CM_ "IMPORT _community.dbc";
CM_ "IMPORT _toyota_2017.dbc";
CM_ "IMPORT _toyota_adas_standard.dbc";

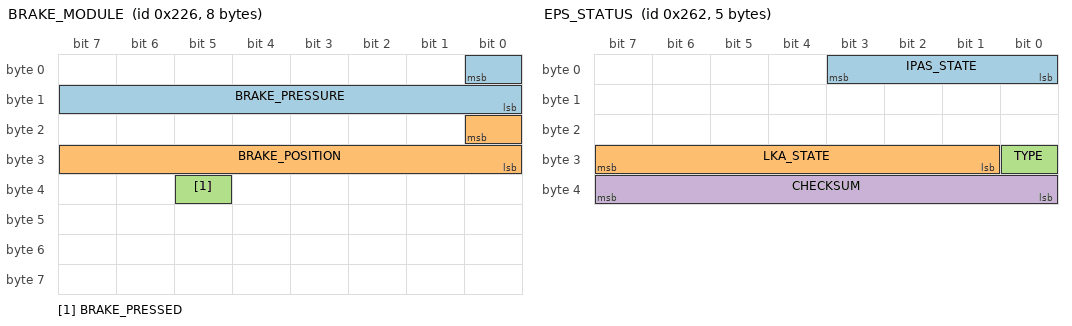
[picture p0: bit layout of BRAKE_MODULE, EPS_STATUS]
BO_ 550 BRAKE_MODULE: 8 XXX
 SG_ BRAKE_PRESSURE : 0|9@0+ (1,0) [0|511] "" XXX
 SG_ BRAKE_POSITION : 16|9@0+ (1,0) [0|511] "" XXX
 SG_ BRAKE_PRESSED : 37|1@0+ (1,0) [0|1] "" XXX

BO_ 610 EPS_STATUS: 5 EPS
 SG_ IPAS_STATE : 3|4@0+ (1,0) [0|15] "" XXX
 SG_ LKA_STATE : 31|7@0+ (1,0) [0|127] "" XXX
 SG_ TYPE : 24|1@0+ (1,0) [0|1] "" XXX
 SG_ CHECKSUM : 39|8@0+ (1,0) [0|255] "" XXX

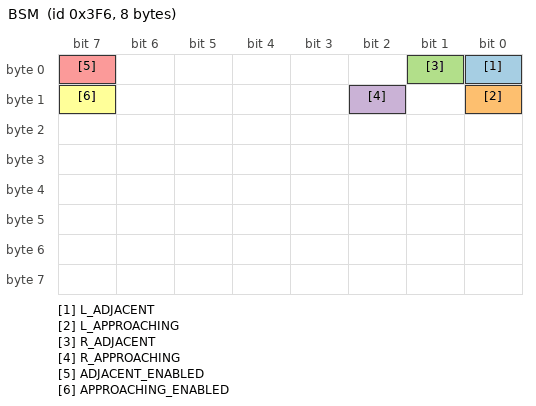
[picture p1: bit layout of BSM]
BO_ 1014 BSM: 8 XXX
 SG_ L_ADJACENT : 0|1@0+ (1,0) [0|1] "" XXX
 SG_ L_APPROACHING : 8|1@0+ (1,0) [0|1] "" XXX
 SG_ R_ADJACENT : 1|1@0+ (1,0) [0|1] "" XXX
 SG_ R_APPROACHING : 10|1@0+ (1,0) [0|1] "" XXX
 SG_ ADJACENT_ENABLED : 7|1@0+ (1,0) [0|1] "" XXX
 SG_ APPROACHING_ENABLED : 15|1@0+ (1,0) [0|1] "" XXX

CM_ SG_ 550 BRAKE_PRESSURE "seems prop to pedal force";
CM_ SG_ 550 BRAKE_POSITION "seems proportional to pedal displacement, unclear the max value of 0x1c8";
CM_ SG_ 610 TYPE "seems 1 on Corolla, 0 on all others";
CM_ SG_ 1014 L_ADJACENT "vehicle adjacent left side of car. enabled above 10mph, regardless of ADJACENT_ENABLED or APPROACHING_ENABLED";
CM_ SG_ 1014 L_APPROACHING "vehicle approaching from left side of car. enabled above 10mph, regardless of ADJACENT_ENABLED or APPROACHING_ENABLED";
CM_ SG_ 1014 R_ADJACENT "vehicle adjacent right side of car. enabled above 10mph, regardless of ADJACENT_ENABLED or APPROACHING_ENABLED";
CM_ SG_ 1014 R_APPROACHING "vehicle approaching from right side of car. enabled above 10mph, regardless of ADJACENT_ENABLED or APPROACHING_ENABLED";
CM_ SG_ 1014 ADJACENT_ENABLED "when BSM is enabled in settings, this is on along with APPROACHING_ENABLED. this controls bsm alert visibility";
CM_ SG_ 1014 APPROACHING_ENABLED "when BSM is enabled in settings, this is on along with ADJACENT_ENABLED. this controls bsm alert visibility";

VAL_ 610 IPAS_STATE 5 "override" 3 "enabled" 1 "disabled";
VAL_ 610 LKA_STATE 25 "temporary_fault" 9 "temporary_fault2" 5 "active" 1 "standby";
